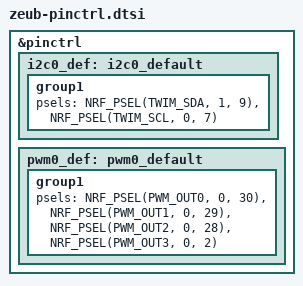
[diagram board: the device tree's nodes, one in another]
&pinctrl {
    i2c0_def: i2c0_default {
        group1 {
            psels = <NRF_PSEL(TWIM_SDA, 1, 9)>, <NRF_PSEL(TWIM_SCL, 0, 7)>;
        };
    };

	pwm0_def: pwm0_default {
		group1 {
			psels = <NRF_PSEL(PWM_OUT0, 0, 30)>, <NRF_PSEL(PWM_OUT1, 0, 29)>,
                  <NRF_PSEL(PWM_OUT2, 0, 28)>, <NRF_PSEL(PWM_OUT3, 0, 2)>;
		};
	};
};
